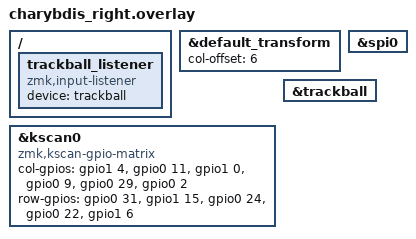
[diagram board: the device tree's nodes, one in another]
#include "charybdis.dtsi"
#include "charybdis_pmw3610.dtsi"
#include "charybdis_wired.dtsi"

// The matrix transform is 6 columns over because the left half is 6 columns wide.
&default_transform {
	col-offset = <6>;
};

&kscan0 {
	compatible = "zmk,kscan-gpio-matrix";
	
	/* columns in reverse order vs stock (C1<->C6, C2<->C5, C3<->C4): bodge wires after PCB repair */
	col-gpios
		= <&gpio1 4  (GPIO_ACTIVE_HIGH | GPIO_PULL_DOWN)>
		, <&gpio0 11 (GPIO_ACTIVE_HIGH | GPIO_PULL_DOWN)>
		, <&gpio1 0  (GPIO_ACTIVE_HIGH | GPIO_PULL_DOWN)>
		, <&gpio0 9 (GPIO_ACTIVE_HIGH | GPIO_PULL_DOWN)>
		, <&gpio0 29 (GPIO_ACTIVE_HIGH | GPIO_PULL_DOWN)>
		, <&gpio0 2 (GPIO_ACTIVE_HIGH | GPIO_PULL_DOWN)>
		;

	row-gpios
    = <&gpio0 31 GPIO_ACTIVE_HIGH>
    , <&gpio1 15 GPIO_ACTIVE_HIGH>  /* NOTE: P1.15 is dead on the current right controller; bt/dongle use P1.11, but here P1.11 is the split UART TX */
    , <&gpio0 24 GPIO_ACTIVE_HIGH>
	  , <&gpio0 22 GPIO_ACTIVE_HIGH>
    , <&gpio1 6  GPIO_ACTIVE_HIGH>
    ;
};

&spi0 {
    status = "okay";
};

&trackball {
    status = "okay";
};

// https://github.com/badjeff/zmk-pmw3610-driver
/ {
  trackball_listener {
    compatible = "zmk,input-listener";
    device = <&trackball>;
  };
};
